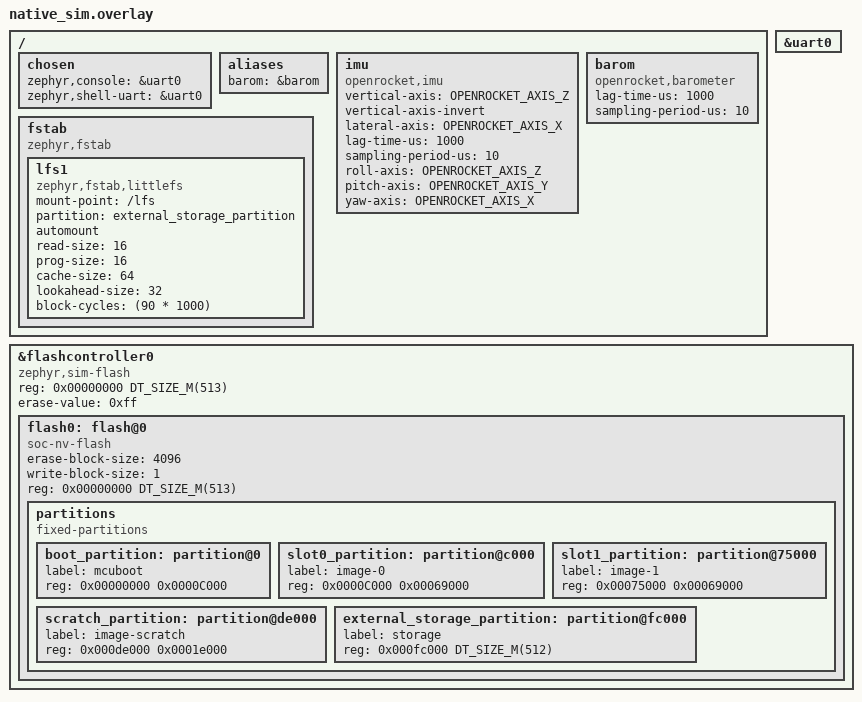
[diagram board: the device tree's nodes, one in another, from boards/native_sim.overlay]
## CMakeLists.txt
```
#-------------------------------------------------------------------------------
# Backplane Deployment Module Application
#
# Copyright (c) 2024 Launch Initiative
# SPDX-License-Identifier: Apache-2.0

cmake_minimum_required(VERSION 3.13.1)
find_package(Zephyr REQUIRED HINTS $ENV{ZEPHYR_BASE})

project(deployment-module LANGUAGES C CXX)

FILE(GLOB sources src/*.c src/*.cpp)
target_include_directories(app PRIVATE include)
target_sources(app PRIVATE ${sources})
```

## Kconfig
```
# Copyright (c) 2024 Launch Initiative
# SPDX-License-Identifier: Apache-2.0

menu "Zephyr"
source "Kconfig.zephyr"
endmenu

module = APP_DEPLOYMENT_MODULE
module-str = APP_DEPLOYMENT_MODULE
source "subsys/logging/Kconfig.template.log_config"
```

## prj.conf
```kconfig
# Copyright (c) 2024 RIT Launch Initiative
# SPDX-License-Identifier: Apache-2.0
CONFIG_ZBUS=y
# ADC
CONFIG_ADC=y
CONFIG_ADC_ASYNC=y

# CPP
CONFIG_CPP=y
CONFIG_REQUIRES_FULL_LIBCPP=y
CONFIG_STD_CPP20=y
CONFIG_CBPRINTF_FP_SUPPORT=y

# Flash
CONFIG_FLASH=y
CONFIG_FLASH_MAP=y
CONFIG_FLASH_PAGE_LAYOUT=y

# Filesystem
CONFIG_FLASH=y
CONFIG_FLASH_MAP=y
CONFIG_FLASH_PAGE_LAYOUT=y
CONFIG_DISK_ACCESS=y
CONFIG_FILE_SYSTEM=y
CONFIG_FILE_SYSTEM_LITTLEFS=y
CONFIG_FS_LITTLEFS_FMP_DEV=y

# Hashmap for UDP
CONFIG_SYS_HASH_MAP=y
CONFIG_SYS_HASH_FUNC32=y

# IO
CONFIG_GPIO=y
CONFIG_I2C=y
# CONFIG_PINCTRL=y
CONFIG_SERIAL=y
CONFIG_LED=y

# OS
CONFIG_POLL=y
CONFIG_MAIN_STACK_SIZE=4096
CONFIG_STACK_USAGE=y
CONFIG_TIMESLICE_SIZE=50

# Settings
CONFIG_SHELL=y
CONFIG_SHELL_TAB=y
CONFIG_SHELL_TAB_AUTOCOMPLETION=y
CONFIG_SETTINGS_RUNTIME=y
CONFIG_SETTINGS=y
CONFIG_SETTINGS_SHELL=y
CONFIG_SETTINGS_FILE=y
CONFIG_SETTINGS_FILE_PATH="/lfs/settings"
CONFIG_REBOOT=y


# SPI
CONFIG_SPI=y
CONFIG_SPI_ASYNC=y
CONFIG_SPI_RTIO=y

# Sensors
CONFIG_SENSOR=y
CONFIG_SENSOR_ASYNC_API=y
```

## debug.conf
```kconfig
# Copyright (c) 2024 Launch Initiative
# SPDX-License-Identifier: Apache-2.0

# Compiler
# CONFIG_DEBUG=y
# CONFIG_DEBUG_OPTIMIZATIONS=y
# CONFIG_DEBUG_THREAD_INFO=y
# CONFIG_THREAD_RUNTIME_STATS=y

# Console
# CONFIG_CBPRINTF_FP_SUPPORT=y
# CONFIG_CONSOLE=y
# CONFIG_CONSOLE_GETCHAR=y
# CONFIG_CONSOLE_GETCHAR_BUFSIZE=64
# CONFIG_CONSOLE_PUTCHAR_BUFSIZE=512
# CONFIG_CONSOLE_SUBSYS=y
# CONFIG_SERIAL=y
# CONFIG_STDOUT_CONSOLE=y
# CONFIG_UART_CONSOLE=y

# Networking
# CONFIG_TFTP_LIB=y

# Shell (common)
CONFIG_SHELL=y
CONFIG_DEVICE_SHELL=y
CONFIG_FILE_SYSTEM_SHELL=y
CONFIG_FLASH_MAP_SHELL=y
CONFIG_GPIO_SHELL=y
CONFIG_KERNEL_SHELL=y
CONFIG_HEAP_MEM_POOL_SIZE=4096

# Shell (networking)
# CONFIG_NET_SHELL=y
# CONFIG_NET_ETHERNET_BRIDGE_SHELL=y

# Shell (unique)
CONFIG_I2C_SHELL=y

# Logging
# CONFIG_APP_DEPLOYMENT_MODULE_LOG_LEVEL_DBG=y
# CONFIG_LOG=y
# 
# Networking
# CONFIG_NET_STATISTICS=y
```

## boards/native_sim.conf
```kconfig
CONFIG_SYS_CLOCK_TICKS_PER_SEC=10000
CONFIG_UBSAN=y

CONFIG_OPENROCKET_SENSORS=y
CONFIG_OPENROCKET_DATA_FILE="data/SimpleRocket.csv"
CONFIG_OPENROCKET_MS_BEFORE_LAUNCH=500000
CONFIG_OPENROCKET_SCALAR_TYPE_DOUBLE=y
CONFIG_OPENROCKET_EVENT_LOG=y

CONFIG_OPENROCKET_IMU=y
CONFIG_OPENROCKET_BAROMETER=y
```

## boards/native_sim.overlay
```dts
/ {
    chosen {
        zephyr,console = &uart0;
        zephyr,shell-uart = &uart0;
    };
    aliases {
        barom = &barom;
    };


    imu: imu {
        status = "okay";
        compatible = "openrocket,imu";
        vertical-axis = "OPENROCKET_AXIS_Z";
        vertical-axis-invert;
        lateral-axis = "OPENROCKET_AXIS_X";
        lag-time-us = <1000>;
        sampling-period-us = <10>;

        roll-axis = "OPENROCKET_AXIS_Z";
        pitch-axis = "OPENROCKET_AXIS_Y";
        yaw-axis = "OPENROCKET_AXIS_X";
    };

    barom: barom {
        status = "okay";
        compatible = "openrocket,barometer";
        lag-time-us = <1000>;
        sampling-period-us = <10>;
    };

    fstab {
        compatible = "zephyr,fstab";
        lfs1: lfs1 {
            compatible = "zephyr,fstab,littlefs";
            mount-point = "/lfs";
            partition = <&external_storage_partition>;
            automount;

            // the binding reccomends defaults for these
            read-size = <16>;
            prog-size = <16>;
            cache-size = <64>; // may need to grow for optimization
            lookahead-size = <32>;
            block-cycles = <(90 * 1000)>;
            // the datasheet gives 100K P-E cycles
            // NOTE: this seems to default to 512 for the mounted filesystem
            // anyway
        };
    };


};

&uart0 {
    status = "okay";
};

&flashcontroller0 {
    status = "okay";
    compatible = "zephyr,sim-flash";
    reg = <0x00000000 DT_SIZE_M(513)>;

    #address-cells = <1>;
    #size-cells = <1>;
    erase-value = <0xff>;

    flash0: flash@0 {
        status = "okay";
        compatible = "soc-nv-flash";
        erase-block-size = <4096>;
        write-block-size = <1>;
        reg = <0x00000000 DT_SIZE_M(513)>; // builtin stuff + external flash simulation

        partitions {
            compatible = "fixed-partitions";
            #address-cells = <1>;
            #size-cells = <1>;

            boot_partition: partition@0 {
                label = "mcuboot";
                reg = <0x00000000 0x0000C000>;
            };
            slot0_partition: partition@c000 {
                label = "image-0";
                reg = <0x0000C000 0x00069000>;
            };
            slot1_partition: partition@75000 {
                label = "image-1";
                reg = <0x00075000 0x00069000>;
            };
            scratch_partition: partition@de000 {
                label = "image-scratch";
                reg = <0x000de000 0x0001e000>;
            };
            external_storage_partition: partition@fc000 {
                label = "storage";
                reg = <0x000fc000 DT_SIZE_M(512)>;
            };
        };
    };
};
```

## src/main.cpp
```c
#include "linear_fit.hpp"
#include "types.h"

#include <f_core/util/debouncer.hpp>
#include <zephyr/device.h>
#include <zephyr/drivers/sensor.h>
#include <zephyr/kernel.h>
#include <zephyr/logging/log.h>
#include <zephyr/settings/settings.h>
#include <zephyr/sys/reboot.h>
#include <zephyr/zbus/zbus.h>
LOG_MODULE_DECLARE(dep_mod);

using SampleType = LinearFitSample<FeetPerSec>;

static constexpr std::size_t gl_window_size = 10;
using GLAvger = MovingAvg<Feet, gl_window_size>;

static constexpr std::size_t window_size = 10;
using SummerType = RollingSum<SampleType, window_size>;

using NoseoverDebouncerT = Debuouncer<ThresholdDirection::Under, FeetPerSec>;
using MainHeightDebouncerT = Debuouncer<ThresholdDirection::Under, Feet>;
using GroundLevelDebouncer = Debuouncer<ThresholdDirection::Under, FeetPerSec>;

Feet calc_alt(KiloPa press_kpa, Celsius temp_c) {
    Scalar pressure = press_kpa * 10;
    Scalar altitude = (1 - pow(pressure / 1'013.25, 0.190284)) * 145'366.45;
    return altitude;
}
static Phase current_phase = Phase::Pad;

Line find_line(const SummerType &summer) {
    std::size_t N = summer.size();
    SampleType E = summer.sum();
    Scalar denom = (N * E.xx - E.x * E.x);
    if (denom == 0) {
        // printf("Would have divided by 0\n");
        return {0, 0};
    }
    Scalar m = (N * E.xy - E.x * E.y) / denom;
    Scalar b = (E.y - m * E.x) / N;
    return {m, b};
}

static void do_state_transition(const struct zbus_channel *chan) { printk("who up transitioning they state"); }

ZBUS_LISTENER_DEFINE(state_transition_lis, do_state_transition);

bool event_validator(const void *msg, size_t msg_size) {
    auto ev = (Timestamped<Event> *) msg;
    printk("Sending State: %d from %d\n", (int) ev->value.typ, (int) ev->value.source);
    if (ev->value.typ == EventType::Noseover) {
        current_phase = Phase::UnderDrogue;
    } else if (ev->value.typ == EventType::Main) {
        current_phase = Phase::UnderMain;
    }

    return false;
}

ZBUS_CHAN_DEFINE(events_chan,                          /* Name */
                 Timestamped<Event>,                   /* Message type */
                 event_validator,                      /* Validator */
                 NULL,                                 /* User Data */
                 ZBUS_OBSERVERS(state_transition_lis), /* observers */
                 ZBUS_MSG_INIT(Timestamped<Event>{0,
                                                  Event{EventType::TurnOn, SensorType::Other}}) /* Initial value {0} */
);

const struct device *imu = DEVICE_DT_GET_ONE(openrocket_imu);
const struct device *barom = DEVICE_DT_GET(DT_ALIAS(barom));

struct AltimCBData {
    const char *label;
    SensorType self;

    GLAvger ground_level_avger;

    SummerType line_fitting_summer;
    NoseoverDebouncerT noseover_debouncer;
    int summer_samples = 0; // we need to get at least window_size samples before any of our data is valid

    MainHeightDebouncerT main_debouncer;

    GroundLevelDebouncer end_of_flight_debouncer;
};

void handle_altim_pad(const Timestamped<altim_telem> *msg, AltimCBData *data, Milliseconds_u32 time_ms, Feet agl_alt) {}
void handle_altim_boosting(const Timestamped<altim_telem> *msg, AltimCBData *data, Milliseconds_u32 time_ms,
                           Feet agl_alt) {}

using altim_callback = void (*)(const Timestamped<altim_telem> *msg, AltimCBData *data, Milliseconds_u32 time_ms,
                                Feet agl_alt);

static altim_callback altim_callbacks[] = {[Phase::Pad] = handle_altim_pad, [Phase::Boostin] = handle_altim_boosting};

static void line_fitting_cb(const struct zbus_channel *chan) {
    const Timestamped<altim_telem> *telem = (Timestamped<altim_telem> *) zbus_chan_const_msg(chan);
    AltimCBData *dat = (AltimCBData *) chan->user_data;

    Milliseconds_u32 time_ms = telem->time;
    Scalar time = time_ms / 1000.0; // we want velocity in ft/s
    Scalar asl_alt = calc_alt(telem->value.press, telem->value.temp);
    Feet agl_alt = asl_alt - dat->ground_level_avger.avg();

    dat->line_fitting_summer.feed(SampleType{time, agl_alt});

    if (current_phase == Phase::Pad) {
        dat->ground_level_avger.feed(asl_alt);

        // ALSO TODO update debouncer to have in range and stable (value doesnt differ by range in time period)

        // also solves boost
        // boost is when altitude is not stable by 500ft in 2 seconds
        //

        return;
    }
    if (current_phase == Phase::UnderMain) {
        dat->main_debouncer.feed(time_ms, agl_alt);
        if (dat->main_debouncer.passed()) {
            Event ev = {.typ = EventType::Main, .source = dat->self};
            Timestamped<Event> tev = {.time = time_ms, .value = ev};
            int err = zbus_chan_pub(&events_chan, &tev, K_SECONDS(1));
            if (err != 0) {
                LOG_ERR("Failed to send main event");
            }
        }
        return;
    }
    // line fit is invalid until we have window_size samples
    dat->summer_samples++;
    if (dat->summer_samples < window_size + 1) {
        return;
    }

    Line l = find_line(dat->line_fitting_summer);
    FeetPerSec vel = l.m;

    dat->noseover_debouncer.feed(time_ms, vel);

    // we nosen over
    if (current_phase == Phase::Coasting && dat->noseover_debouncer.passed()) {
        Event ev;
        ev.source = dat->self;
        ev.typ = EventType::Noseover;
        Timestamped<Event> tev = {.time = time_ms, .value = ev};
        printk("here\n");

        int err = zbus_chan_pub(&events_chan, &tev, K_SECONDS(1));
        if (err != 0) {
            LOG_ERR("Failed to write noseover event");
        }
    }

    // LOG_INF("From listener -> telem p=%f, t=%f", (double) telem->value.press, (double) telem->value.temp);
}

ZBUS_LISTENER_DEFINE(bme_lis, line_fitting_cb);

AltimCBData bmecbd{
    .label = "bme280",
    .self = SensorType::BME280,
    .ground_level_avger = GLAvger{0.0},
    .line_fitting_summer = RollingSum<SampleType, window_size>{LinearFitSample<Scalar>{}},
    .noseover_debouncer = NoseoverDebouncerT{0, 0},
    .main_debouncer = MainHeightDebouncerT{0, 0},
    .end_of_flight_debouncer = GroundLevelDebouncer{0, 0}, // TODO make these defaults
};

ZBUS_CHAN_DEFINE(bme_telem_chan,                                               /* Name */
                 Timestamped<altim_telem>,                                     /* Message type */
                 NULL,                                                         /* Validator */
                 &bmecbd,                                                      /* User Data */
                 ZBUS_OBSERVERS(bme_lis),                                      /* observers */
                 ZBUS_MSG_INIT(Timestamped<altim_telem>{0, altim_telem{0, 0}}) /* Initial value {0} */
);

int main() {
    Feet main_height = 500;
    Milliseconds_u32 main_time = 100;

    FeetPerSec noseover_velocity = 10;
    Milliseconds_u32 noseover_time = 100;

    bmecbd.noseover_debouncer = NoseoverDebouncerT{noseover_time, noseover_velocity};
    bmecbd.main_debouncer = MainHeightDebouncer{main_time, main_height};

    int i = 0;
    while (true) {

        struct sensor_value pressure;
        struct sensor_value temp;
        int err = sensor_sample_fetch(barom);
        if (err < 0) {
            printk("err fetching");
        }
        err = sensor_channel_get(barom, SENSOR_CHAN_PRESS, &pressure);
        if (err < 0) {
            printk("err getting");
        }
        err = sensor_channel_get(barom, SENSOR_CHAN_AMBIENT_TEMP, &temp);
        if (err < 0) {
            printk("err getting");
        }
        uint64_t ms = k_uptime_get();
        if (ms > 3860 && current_phase == Phase::Boostin) {
            current_phase = Phase::Coasting;
        } else if (ms > 2000 && current_phase == Phase::Pad) {
            current_phase = Phase::Boostin;
        }

        Timestamped<altim_telem> telem = {};
        telem.time = ms;
        telem.value.press = sensor_value_to_float(&pressure);
        telem.value.temp = sensor_value_to_float(&temp);
        int got = zbus_chan_pub(&bme_telem_chan, &telem, K_SECONDS(1));
        if (got != 0) {
            printk("Err: %d\n", got);
        }
        i++;
        // printk("published\n");
        k_msleep(10);
    }
}
```

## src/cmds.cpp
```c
#include "types.h"

#include <f_core/util/debouncer.hpp>
#include <zephyr/settings/settings.h>
#include <zephyr/shell/shell.h>

bool settings_modified = false;

static int noseover_detect_mix_handler(const struct shell *sh, size_t argc, char **argv, void *data) {
    shell_print(sh, "UNIMPLEMENTED");
    return 0;
}

static int boost_detect_mix_handler(const struct shell *sh, size_t argc, char **argv, void *data) {
    int gain;

    /* data is a value corresponding to called command syntax */
    gain = (int) data;
    // adc_set_gain(gain);
    shell_print(sh, "UNIMPLEMENTED");

    shell_print(sh,
                "Boost mix: %s\n"
                "Value sent: %d",
                argv[0], gain);

    return 0;
}

static int cmd_noseover_vel_handler(const struct shell *sh, size_t argc, char **argv, void *data) {
    shell_print(sh, "UNIMPLEMENTED");
    shell_print(sh, "Me when i uhhhhhh %s", argv[0]);
    return 0;
}

int shell_get_char(const struct shell *sh, char *outc) {
    size_t cnt = 0;
    char c = 1;
    int err = sh->iface->api->read(sh->iface, &c, sizeof(c), &cnt);
    if (err != 0) {
        return err;
    }
    while (cnt == 0) {
        k_msleep(1);
        sh->iface->api->read(sh->iface, &c, sizeof(c), &cnt);
        if (err != 0) {
            return err;
        }
    }
    *outc = c;
    return 0;
}

bool validate_number(const struct shell *sh, char *number) {
    // convert to numbers

    for (int i = 0; i < 16; i++) {
        char c = number[i];
        if (c < '0' || c > '9') {
            shell_print(sh, "Invalid character '%c' at position %d", c, i);
            return false;
        }
        number[i] = c - '0';
    }
    // last_digit, remaining_numbers = self.last_digit_and_remaining_numbers()
    // nums = [int(num) if idx % 2 != 0 else int(num) * 2 if int(num) * 2 <= 9
    // else int(num) * 2 % 10 + int(num) * 2 // 10
    // for idx, num in enumerate(reversed(remaining_numbers))]
    char last = number[15];
    int sum = 0;

    for (int i = 14; i >= 0; i--) {
        int idx = 14 - i;
        int num = number[i];

        int out = 0;
        if (idx % 2 != 0) {
            out = num;
        } else if (num * 2 <= 9) {
            out = num * 2;
        } else {
            out = num * 2 % 10 + (num * 2) / 10;
        }
        sum += out;
    }
    return (sum + (int) last) % 10 == 0;
}
static int deploy_handler(const struct shell *sh, size_t argc, char **argv, void *data) {
    // int which = (int) data;
    // auto channel = static_cast<DeploymentChannel>(which);
    char *which_str = argv[0];

    // y/n
    shell_fprintf(sh, SHELL_NORMAL, "Do you want to deploy %s? (y/n): ", which_str);
    char c = 0;
    int err = shell_get_char(sh, &c);
    if (err != 0) {
        shell_print(sh, "Couldn't read: %d", err);
        return err;
    }
    if (c != 'y') {
        shell_print(sh, "Not deploying");
        return 0;
    }
    // Credit card number
    shell_print(sh, "%c", c);

    shell_warn(sh, "Enter a 16 digit credit card number to make sure you didn't just sit on the keyboard\nNo spaces, "
                   "just numbers, no backspaces:");
    char buf[16] = {0};
    for (int i = 0; i < 16; i++) {
        int err = shell_get_char(sh, &buf[i]);
        if (err != 0) {
            shell_print(sh, "Couldn't read: %d", err);
            return err;
        }
        size_t cnt = 0;
        sh->iface->api->write(sh->iface, &buf[i], sizeof(char), &cnt);
    }
    if (!validate_number(sh, buf)) {
        shell_print(sh, "\nInvalid Card Number");
        return -1;
    }
    // y
    shell_print(sh, "\nNumber validated, you're a human");
    shell_warn(sh, "PRESS 'y' TO START");

    c = 0;
    err = shell_get_char(sh, &c);
    if (err != 0) {
        shell_print(sh, "Couldn't read: %d", err);
        return err;
    }
    if (c != 'y') {
        return 0;
    }

    shell_error(sh, "DEPLOYING %s. GOOD LUCK", which_str);
    return 0;
}

// clang-format off

SHELL_SUBCMD_DICT_SET_CREATE(sub_noseover_detect_mix, noseover_detect_mix_handler, 
                            (Or, MixStrategy::Or, "or"), 
                            (And, MixStrategy::And, "and")
                            );

SHELL_SUBCMD_DICT_SET_CREATE(sub_deploy, deploy_handler, 
                            (main, DeploymentChannel::Main, "main"), 
                            (drogue, DeploymentChannel::Drogue, "drogue")
                            );

SHELL_SUBCMD_DICT_SET_CREATE(sub_boost_detect_mix, boost_detect_mix_handler, 
                            (accel, BoostDetectMix::Accel, "accelerometer"), 
                            (altim, BoostDetectMix::Altimeter, "altimeter"),
                            (both, BoostDetectMix::Both, "both"),
                            (either, BoostDetectMix::Either, "either")
                            );

SHELL_STATIC_SUBCMD_SET_CREATE(sub_noseover, 
                                SHELL_CMD(velocity, NULL, "What velocity do we decide noseover at. 0 for perfect noseover (+ delay from filtering). +X for X ft/s going upwards. -X for X ft/s going down", cmd_noseover_vel_handler),
                                SHELL_CMD(mix, &sub_noseover_detect_mix, "How to mix the two barometers' noseover detections (or, and)", NULL),
                               SHELL_SUBCMD_SET_END);


SHELL_STATIC_SUBCMD_SET_CREATE(sub_boost, 
                                SHELL_CMD(mix, &sub_boost_detect_mix, "How do we mix the boost detection methods  (accel, altim, both, either)", NULL),
                               SHELL_SUBCMD_SET_END);

SHELL_STATIC_SUBCMD_SET_CREATE(sub_drogue, 
                                // SHELL_CMD(mix, &sub_boost_detect_mix, "How do we mix the boost detection methods  (accel, altim, both, either)", NULL),
                               SHELL_SUBCMD_SET_END);


SHELL_STATIC_SUBCMD_SET_CREATE(sub_demo, 
                                SHELL_CMD(boost, &sub_boost, "Parameters for boost detection", NULL),
                                SHELL_CMD(noseover, &sub_noseover, "Parameters for noseover detection. The main charge is activated at noseover", NULL),
                                SHELL_CMD(drogue, &sub_drogue, "Parameters for drogue activation", NULL),
                                SHELL_CMD(deploy, &sub_deploy, "Deploy main or drogue as a test", NULL),
                               SHELL_SUBCMD_SET_END);

SHELL_CMD_REGISTER(flight, &sub_demo, "Commands for deployment mod", NULL);
```

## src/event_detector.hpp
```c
#pragma once
#include <stdint.h>

enum class Phase { NoChange, Pad, Boost, Coast, PostNoseover, PostMain, Ground, StopFlight };
struct PhaseEvent {
    Phase nextphase = Phase::NoChange;
    uint32_t offset_ms = 0;
};

class EventDetector {
    virtual PhaseEvent PadCallback() { return {}; }
    virtual PhaseEvent BoostCallback() { return {}; }
    virtual PhaseEvent CoastCallback() { return {}; }
    virtual PhaseEvent PostNoseoverCallback() { return {}; }
    virtual PhaseEvent PostMainCallback() { return {}; }
    virtual PhaseEvent GroundCallback() { return {}; }
};
```

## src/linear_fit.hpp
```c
#include "f_core/util/circular_buffer.hpp"

#include <array>
#include <cstddef>

template <typename T, std::size_t len> class RollingSum {
  public:
    static_assert(len > 0, "What is the sum of 0 elements?");

    using value_type = T;
    static constexpr std::size_t size_ = len;

    RollingSum(T start) : buf(start) { fill(start); }

    constexpr std::size_t size() const { return size_; }

    void fill(const value_type &start) {
        buf.fill(start);
        total = buf.oldest_sample();
        for (std::size_t i = 1; i < buf.size(); i++) {
            total = total + buf[1];
        }
    }

    void feed(value_type value) {
        value_type oldest = buf.oldest_sample();
        total = total - oldest;
        total = total + value;
        buf.add_sample(value);
    }
    value_type sum() const { return total; }

  private:
    value_type total;
    CircularBuffer<value_type, size_> buf;
};

template <typename T, std::size_t len> class MovingAvg {
  public:
    using value_type = T;
    static constexpr std::size_t length = len;

    MovingAvg(value_type start) : summer(start) {}

    void feed(value_type value) { summer.feed(value); }
    value_type avg() { return summer.sum() / (value_type) len; }
    void fill(const T &start) { summer.fill(start); }

  private:
    RollingSum<value_type, len> summer;
};

template <typename T> class LinearFitSample {

  public:
    using SampleT = T;
    LinearFitSample() : LinearFitSample(0, 0) {}
    LinearFitSample(T x, T y) : x(x), y(y), xx(x * x), xy(x * y) {}
    LinearFitSample(T x, T y, T xx, T xy) : x(x), y(y), xx(xx), xy(xy) {}

    LinearFitSample operator+(const LinearFitSample &o) const {
        return LinearFitSample{x + o.x, y + o.y, xx + o.xx, xy + o.xy};
    }
    LinearFitSample operator-(const LinearFitSample &o) const {
        return LinearFitSample{x - o.x, y - o.y, xx - o.xx, xy - o.xy};
    }

    T x, y, xx, xy;
};
```

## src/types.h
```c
#include <cstdint>
#include <math.h>

enum class DeploymentChannel { Main = 1, Drogue = 2 };
enum class MixStrategy { Or = 1, And = 2 };
enum class BoostDetectMix { Accel = 1, Altimeter = 2, Both = 3, Either = 4 };

enum class SensorType { Other, BME280, MS5611, IMU };
enum class EventType { TurnOn, Boost, Noseover, Main };

enum class Phase {
    Unknown,
    Pad,
    Boostin,
    Coasting,
    UnderDrogue,
    UnderMain,
    OnGround,
};

struct altim_telem {
    float temp;
    float press;
};

template <typename Value, typename TimestampT = uint32_t> struct Timestamped {
    using value_type = Value;
    using timestamp_type = TimestampT;

    timestamp_type time;
    value_type value;
};

using Scalar = double;
using FeetPerSec = Scalar;

using Milliseconds_u32 = uint32_t;
using Feet = Scalar;
using KiloPa = Scalar;
using Celsius = Scalar;

struct Event {
    EventType typ;
    SensorType source;
};

struct Line {
    Scalar m;
    Scalar b;
};
```
